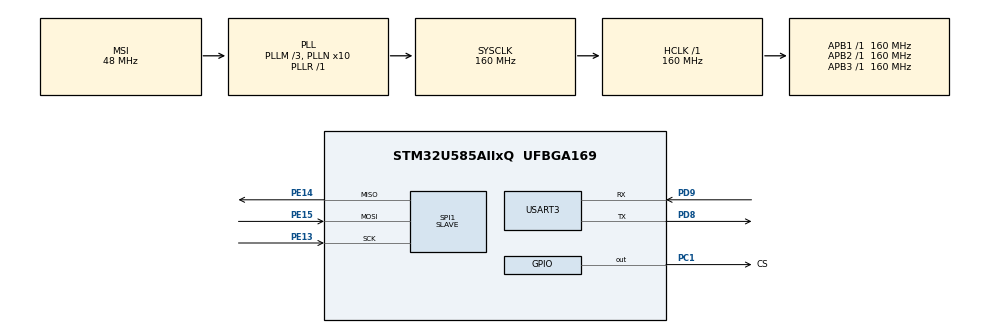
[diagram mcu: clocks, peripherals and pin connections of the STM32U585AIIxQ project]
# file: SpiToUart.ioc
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CORTEX_M33_NS.userName=CORTEX_M33
Mcu.Family=STM32U5
Mcu.Name=STM32U585AIIxQ
Mcu.Package=UFBGA169
NVIC.PriorityGroup=NVIC_PRIORITYGROUP_4
PC1.GPIO_Label=CS
PC1.GPIO_Speed=GPIO_SPEED_FREQ_HIGH
PC1.PinState=GPIO_PIN_SET
PC1.Signal=GPIO_Output
PD8.Mode=Asynchronous
PD8.Signal=USART3_TX
PD9.Mode=Asynchronous
PD9.Signal=USART3_RX
PE13.Mode=Full_Duplex_Slave
PE13.Signal=SPI1_SCK
PE14.Mode=Full_Duplex_Slave
PE14.Signal=SPI1_MISO
PE15.Mode=Full_Duplex_Slave
PE15.Signal=SPI1_MOSI
ProjectManager.HeapSize=0x200
ProjectManager.StackSize=0x400
ProjectManager.TargetToolchain=STM32CubeIDE
RCC.ADCFreq_Value=16000000
RCC.AHBFreq_Value=160000000
RCC.APB1Freq_Value=160000000
RCC.APB1TimFreq_Value=160000000
RCC.APB2Freq_Value=160000000
RCC.APB2TimFreq_Value=160000000
RCC.APB3Freq_Value=160000000
RCC.CortexFreq_Value=160000000
RCC.EPOD_VALUE=48000000
RCC.HCLKFreq_Value=160000000
RCC.HSE_VALUE=16000000
RCC.HSI48_VALUE=48000000
RCC.HSI_VALUE=16000000
RCC.LSE_VALUE=32768
RCC.LSIDIV_VALUE=32000
RCC.MSIClockRange=RCC_MSIRANGE_0
RCC.MSI_VALUE=48000000
RCC.PLL1R=1
RCC.PLLFRACN=0
RCC.PLLM=3
RCC.PLLN=10
RCC.SYSCLKFreq_VALUE=160000000
RCC.SYSCLKSource=RCC_SYSCLKSOURCE_PLLCLK
RCC.USBFreq_Value=48000000
RCC.VCOOutputFreq_Value=160000000
SPI1.DataSize=SPI_DATASIZE_8BIT
SPI1.Direction=SPI_DIRECTION_2LINES
SPI1.Mode=SPI_MODE_SLAVE
SPI1.VirtualType=VM_SLAVE
USART3.VirtualMode-Asynchronous=VM_ASYNC
VP_LPBAMQUEUE_VS_QUEUE.Mode=QUEUEMODE
VP_LPBAM_VS_SIG1.Mode=SmartRun
VP_LPBAM_VS_SIG4.Mode=LPDMA1
VP_MEMORYMAP_VS_MEMORYMAP.Mode=CurAppReg
VP_PWR_VS_SECSignals.Mode=Security/Privilege
board=custom

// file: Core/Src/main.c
/* USER CODE BEGIN Header */
/**
  ******************************************************************************
  * @file           : main.c
  * @brief          : Main program body
  ******************************************************************************
  * @attention
  *
  * Copyright (c) 2024 STMicroelectronics.
  * All rights reserved.
  *
  * This software is licensed under terms that can be found in the LICENSE file
  * in the root directory of this software component.
  * If no LICENSE file comes with this software, it is provided AS-IS.
  *
  ******************************************************************************
  */
/* USER CODE END Header */
#include "main.h"

SPI_HandleTypeDef hspi1;

UART_HandleTypeDef huart3;

void SystemClock_Config(void);
static void MX_GPIO_Init(void);
static void MX_SPI1_Init(void);
static void MX_USART3_UART_Init(void);

int main(void)
{

  /* MCU Configuration--------------------------------------------------------*/

  /* Reset of all peripherals, Initializes the Flash interface and the Systick. */
  HAL_Init();

  /* Configure the system clock */
  SystemClock_Config();

  /* Initialize all configured peripherals */
  MX_GPIO_Init();
  MX_SPI1_Init();
  MX_USART3_UART_Init();

  /* Infinite loop */
  /* USER CODE BEGIN WHILE */

  uint8_t txData[] = "Hello UART!";
  uint8_t rxData[20];
  uint8_t spi_rx_buffer[20];
// SPI to UART
  while (1)
  {
    /* USER CODE END WHILE */
	  if (HAL_SPI_Receive(&hspi1, spi_rx_buffer, sizeof(spi_rx_buffer), HAL_MAX_DELAY) == HAL_OK)
	  {
		/* Transmit received data over UART */
		UART_Transmit(spi_rx_buffer, HAL_MAX_DELAY);
	  }

	  if(UART_Receive(rxData, sizeof(rxData)) == HAL_OK)
	  {
		HAL_SPI_Transmit(&hspi1, rxData, sizeof(rxData),HAL_MAX_DELAY);
	  }
//	    printf("Received data: %s\r\n", rxData);
//	    memset(rxData, 0, sizeof(rxData));

  }
}

void SystemClock_Config(void)
{
  RCC_OscInitTypeDef RCC_OscInitStruct = {0};
  RCC_ClkInitTypeDef RCC_ClkInitStruct = {0};

  /** Configure the main internal regulator output voltage
  */
  if (HAL_PWREx_ControlVoltageScaling(PWR_REGULATOR_VOLTAGE_SCALE1) != HAL_OK)
  {
    Error_Handler();
  }

  /** Initializes the CPU, AHB and APB buses clocks
  */
  RCC_OscInitStruct.OscillatorType = RCC_OSCILLATORTYPE_MSI;
  RCC_OscInitStruct.MSIState = RCC_MSI_ON;
  RCC_OscInitStruct.MSICalibrationValue = RCC_MSICALIBRATION_DEFAULT;
  RCC_OscInitStruct.MSIClockRange = RCC_MSIRANGE_0;
  RCC_OscInitStruct.PLL.PLLState = RCC_PLL_ON;
  RCC_OscInitStruct.PLL.PLLSource = RCC_PLLSOURCE_MSI;
  RCC_OscInitStruct.PLL.PLLMBOOST = RCC_PLLMBOOST_DIV4;
  RCC_OscInitStruct.PLL.PLLM = 3;
  RCC_OscInitStruct.PLL.PLLN = 10;
  RCC_OscInitStruct.PLL.PLLP = 2;
  RCC_OscInitStruct.PLL.PLLQ = 2;
  RCC_OscInitStruct.PLL.PLLR = 1;
  RCC_OscInitStruct.PLL.PLLRGE = RCC_PLLVCIRANGE_1;
  RCC_OscInitStruct.PLL.PLLFRACN = 0;
  if (HAL_RCC_OscConfig(&RCC_OscInitStruct) != HAL_OK)
  {
    Error_Handler();
  }

  /** Initializes the CPU, AHB and APB buses clocks
  */
  RCC_ClkInitStruct.ClockType = RCC_CLOCKTYPE_HCLK|RCC_CLOCKTYPE_SYSCLK
                              |RCC_CLOCKTYPE_PCLK1|RCC_CLOCKTYPE_PCLK2
                              |RCC_CLOCKTYPE_PCLK3;
  RCC_ClkInitStruct.SYSCLKSource = RCC_SYSCLKSOURCE_PLLCLK;
  RCC_ClkInitStruct.AHBCLKDivider = RCC_SYSCLK_DIV1;
  RCC_ClkInitStruct.APB1CLKDivider = RCC_HCLK_DIV1;
  RCC_ClkInitStruct.APB2CLKDivider = RCC_HCLK_DIV1;
  RCC_ClkInitStruct.APB3CLKDivider = RCC_HCLK_DIV1;

  if (HAL_RCC_ClockConfig(&RCC_ClkInitStruct, FLASH_LATENCY_4) != HAL_OK)
  {
    Error_Handler();
  }
}

static void MX_SPI1_Init(void)
{

  SPI_AutonomousModeConfTypeDef HAL_SPI_AutonomousMode_Cfg_Struct = {0};

  /* SPI1 parameter configuration*/
  hspi1.Instance = SPI1;
  hspi1.Init.Mode = SPI_MODE_SLAVE;
  hspi1.Init.Direction = SPI_DIRECTION_2LINES;
  hspi1.Init.DataSize = SPI_DATASIZE_8BIT;
  hspi1.Init.CLKPolarity = SPI_POLARITY_LOW;
  hspi1.Init.CLKPhase = SPI_PHASE_1EDGE;
  hspi1.Init.NSS = SPI_NSS_SOFT;
  hspi1.Init.FirstBit = SPI_FIRSTBIT_MSB;
  hspi1.Init.TIMode = SPI_TIMODE_DISABLE;
  hspi1.Init.CRCCalculation = SPI_CRCCALCULATION_DISABLE;
  hspi1.Init.CRCPolynomial = 0x7;
  hspi1.Init.NSSPMode = SPI_NSS_PULSE_DISABLE;
  hspi1.Init.NSSPolarity = SPI_NSS_POLARITY_LOW;
  hspi1.Init.FifoThreshold = SPI_FIFO_THRESHOLD_01DATA;
  hspi1.Init.MasterSSIdleness = SPI_MASTER_SS_IDLENESS_00CYCLE;
  hspi1.Init.MasterInterDataIdleness = SPI_MASTER_INTERDATA_IDLENESS_00CYCLE;
  hspi1.Init.MasterReceiverAutoSusp = SPI_MASTER_RX_AUTOSUSP_DISABLE;
  hspi1.Init.MasterKeepIOState = SPI_MASTER_KEEP_IO_STATE_DISABLE;
  hspi1.Init.IOSwap = SPI_IO_SWAP_DISABLE;
  hspi1.Init.ReadyMasterManagement = SPI_RDY_MASTER_MANAGEMENT_INTERNALLY;
  hspi1.Init.ReadyPolarity = SPI_RDY_POLARITY_HIGH;
  if (HAL_SPI_Init(&hspi1) != HAL_OK)
  {
    Error_Handler();
  }
  HAL_SPI_AutonomousMode_Cfg_Struct.TriggerState = SPI_AUTO_MODE_DISABLE;
  HAL_SPI_AutonomousMode_Cfg_Struct.TriggerSelection = SPI_GRP1_GPDMA_CH0_TCF_TRG;
  HAL_SPI_AutonomousMode_Cfg_Struct.TriggerPolarity = SPI_TRIG_POLARITY_RISING;
  if (HAL_SPIEx_SetConfigAutonomousMode(&hspi1, &HAL_SPI_AutonomousMode_Cfg_Struct) != HAL_OK)
  {
    Error_Handler();
  }

}

static void MX_USART3_UART_Init(void)
{

  huart3.Instance = USART3;
  huart3.Init.BaudRate = 115200;
  huart3.Init.WordLength = UART_WORDLENGTH_8B;
  huart3.Init.StopBits = UART_STOPBITS_1;
  huart3.Init.Parity = UART_PARITY_NONE;
  huart3.Init.Mode = UART_MODE_TX_RX;
  huart3.Init.HwFlowCtl = UART_HWCONTROL_NONE;
  huart3.Init.OverSampling = UART_OVERSAMPLING_16;
  huart3.Init.OneBitSampling = UART_ONE_BIT_SAMPLE_DISABLE;
  huart3.Init.ClockPrescaler = UART_PRESCALER_DIV1;
  huart3.AdvancedInit.AdvFeatureInit = UART_ADVFEATURE_NO_INIT;
  if (HAL_UART_Init(&huart3) != HAL_OK)
  {
    Error_Handler();
  }
  if (HAL_UARTEx_SetTxFifoThreshold(&huart3, UART_TXFIFO_THRESHOLD_1_8) != HAL_OK)
  {
    Error_Handler();
  }
  if (HAL_UARTEx_SetRxFifoThreshold(&huart3, UART_RXFIFO_THRESHOLD_1_8) != HAL_OK)
  {
    Error_Handler();
  }
  if (HAL_UARTEx_DisableFifoMode(&huart3) != HAL_OK)
  {
    Error_Handler();
  }

}
void UART_Transmit(uint8_t *pData, uint16_t Size)
{
  HAL_UART_Transmit(&huart3, pData, Size, HAL_MAX_DELAY);
}

void UART_Receive(uint8_t *pData, uint16_t Size)
{
  HAL_UART_Receive(&huart3, pData, Size, HAL_MAX_DELAY);
}

static void MX_GPIO_Init(void)
{
  GPIO_InitTypeDef GPIO_InitStruct = {0};

  /* GPIO Ports Clock Enable */
  __HAL_RCC_GPIOC_CLK_ENABLE();
  __HAL_RCC_GPIOE_CLK_ENABLE();
  __HAL_RCC_GPIOD_CLK_ENABLE();

  /*Configure GPIO pin Output Level */
  HAL_GPIO_WritePin(CS_GPIO_Port, CS_Pin, GPIO_PIN_SET);

  /*Configure GPIO pin : CS_Pin */
  GPIO_InitStruct.Pin = CS_Pin;
  GPIO_InitStruct.Mode = GPIO_MODE_OUTPUT_PP;
  GPIO_InitStruct.Pull = GPIO_NOPULL;
  GPIO_InitStruct.Speed = GPIO_SPEED_FREQ_HIGH;
  HAL_GPIO_Init(CS_GPIO_Port, &GPIO_InitStruct);

}

void Error_Handler(void)
{
  __disable_irq();
  while (1)
  {
  }
}
